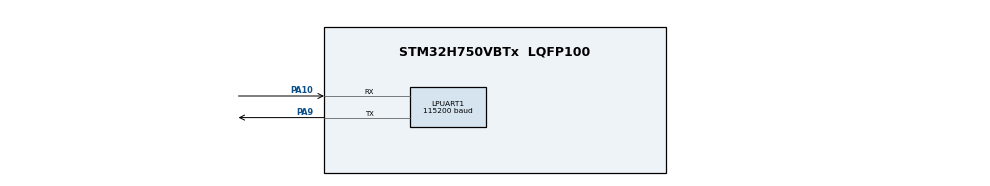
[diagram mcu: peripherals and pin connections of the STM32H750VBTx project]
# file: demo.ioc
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Bdma.LPUART1_RX.0.Direction=DMA_PERIPH_TO_MEMORY
Bdma.LPUART1_RX.0.EventEnable=DISABLE
Bdma.LPUART1_RX.0.Instance=BDMA_Channel0
Bdma.LPUART1_RX.0.MemDataAlignment=DMA_MDATAALIGN_BYTE
Bdma.LPUART1_RX.0.MemInc=DMA_MINC_ENABLE
Bdma.LPUART1_RX.0.Mode=DMA_NORMAL
Bdma.LPUART1_RX.0.PeriphDataAlignment=DMA_PDATAALIGN_BYTE
Bdma.LPUART1_RX.0.PeriphInc=DMA_PINC_DISABLE
Bdma.LPUART1_RX.0.Polarity=HAL_DMAMUX_REQ_GEN_RISING
Bdma.LPUART1_RX.0.Priority=DMA_PRIORITY_LOW
Bdma.LPUART1_RX.0.RequestNumber=1
Bdma.LPUART1_RX.0.SignalID=NONE
Bdma.LPUART1_RX.0.SyncEnable=DISABLE
Bdma.LPUART1_RX.0.SyncPolarity=HAL_DMAMUX_SYNC_NO_EVENT
Bdma.LPUART1_RX.0.SyncRequestNumber=1
Bdma.LPUART1_RX.0.SyncSignalID=NONE
Bdma.LPUART1_TX.1.Direction=DMA_MEMORY_TO_PERIPH
Bdma.LPUART1_TX.1.EventEnable=DISABLE
Bdma.LPUART1_TX.1.Instance=BDMA_Channel1
Bdma.LPUART1_TX.1.MemDataAlignment=DMA_MDATAALIGN_BYTE
Bdma.LPUART1_TX.1.MemInc=DMA_MINC_ENABLE
Bdma.LPUART1_TX.1.Mode=DMA_NORMAL
Bdma.LPUART1_TX.1.PeriphDataAlignment=DMA_PDATAALIGN_BYTE
Bdma.LPUART1_TX.1.PeriphInc=DMA_PINC_DISABLE
Bdma.LPUART1_TX.1.Polarity=HAL_DMAMUX_REQ_GEN_RISING
Bdma.LPUART1_TX.1.Priority=DMA_PRIORITY_LOW
Bdma.LPUART1_TX.1.RequestNumber=1
Bdma.LPUART1_TX.1.SignalID=NONE
Bdma.LPUART1_TX.1.SyncEnable=DISABLE
Bdma.LPUART1_TX.1.SyncPolarity=HAL_DMAMUX_SYNC_NO_EVENT
Bdma.LPUART1_TX.1.SyncRequestNumber=1
Bdma.LPUART1_TX.1.SyncSignalID=NONE
Bdma.Request0=LPUART1_RX
Bdma.Request1=LPUART1_TX
Bdma.RequestsNb=2
CORTEX_M7.AccessPermission-Cortex_Memory_Protection_Unit_Region2_Settings=MPU_REGION_FULL_ACCESS
CORTEX_M7.BaseAddress-Cortex_Memory_Protection_Unit_Region2_Settings=0x24000000
CORTEX_M7.Enable-Cortex_Memory_Protection_Unit_Region0_Settings=__NULL
CORTEX_M7.Enable-Cortex_Memory_Protection_Unit_Region2_Settings=MPU_REGION_ENABLE
CORTEX_M7.IsCacheable-Cortex_Memory_Protection_Unit_Region2_Settings=MPU_ACCESS_CACHEABLE
CORTEX_M7.IsShareable-Cortex_Memory_Protection_Unit_Region2_Settings=MPU_ACCESS_SHAREABLE
CORTEX_M7.MPU_Control=__NULL
CORTEX_M7.Size-Cortex_Memory_Protection_Unit_Region2_Settings=MPU_REGION_SIZE_512KB
LPUART1.BaudRate=115200
LPUART1.FIFOMode=UART_FIFOMODE_DISABLE
Mcu.Family=STM32H7
Mcu.Name=STM32H750VBTx
Mcu.Package=LQFP100
NVIC.BDMA_Channel0_IRQn=true\:0\:0\:false\:false\:true\:true\:true\:true
NVIC.BDMA_Channel1_IRQn=true\:0\:0\:false\:false\:true\:false\:true\:true
NVIC.LPUART1_IRQn=true\:0\:0\:false\:false\:true\:true\:true\:true
NVIC.PriorityGroup=NVIC_PRIORITYGROUP_4
PA10.Mode=Asynchronous
PA10.Signal=LPUART1_RX
PA9.Mode=Asynchronous
PA9.Signal=LPUART1_TX
PC14-OSC32_IN\ (OSC32_IN).Mode=LSE-External-Oscillator
PC14-OSC32_IN\ (OSC32_IN).Signal=RCC_OSC32_IN
PC15-OSC32_OUT\ (OSC32_OUT).Mode=LSE-External-Oscillator
PC15-OSC32_OUT\ (OSC32_OUT).Signal=RCC_OSC32_OUT
PH0-OSC_IN\ (PH0).Mode=HSE-External-Oscillator
PH0-OSC_IN\ (PH0).Signal=RCC_OSC_IN
PH1-OSC_OUT\ (PH1).Mode=HSE-External-Oscillator
PH1-OSC_OUT\ (PH1).Signal=RCC_OSC_OUT
ProjectManager.HeapSize=0x200
ProjectManager.StackSize=0x400
ProjectManager.TargetToolchain=MDK-ARM V5.32
RCC.ADCFreq_Value=129000000
RCC.APB1Freq_Value=64000000
RCC.APB2Freq_Value=32000000
RCC.APB3Freq_Value=32000000
RCC.APB4Freq_Value=64000000
RCC.CortexFreq_Value=64000000
RCC.D1PPRE=RCC_APB3_DIV2
RCC.D2PPRE2=RCC_APB2_DIV2
RCC.HCLKFreq_Value=64000000
RCC.SYSCLKFreq_VALUE=64000000
RCC.USBFreq_Value=129000000
board=custom

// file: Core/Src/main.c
/* USER CODE BEGIN Header */
/**
  ******************************************************************************
  * @file           : main.c
  * @brief          : Main program body
  ******************************************************************************
  * @attention
  *
  * Copyright (c) 2023 STMicroelectronics.
  * All rights reserved.
  *
  * This software is licensed under terms that can be found in the LICENSE file
  * in the root directory of this software component.
  * If no LICENSE file comes with this software, it is provided AS-IS.
  *
  ******************************************************************************
  */
/* USER CODE END Header */
#include "main.h"
#include "bdma.h"
#include "usart.h"
#include "gpio.h"

/* USER CODE BEGIN Includes */
#include "stdio.h"
#include "stm32h750xx.h"
/* USER CODE END Includes */

/* USER CODE BEGIN PV */
extern uint8_t rx_len;
extern uint8_t recv_end_flag;
extern uint8_t rx_buffer[200];
extern uint8_t tx_buffer[200];
extern DMA_HandleTypeDef hdma_lpuart1_tx;

/* USER CODE END PV */

void SystemClock_Config(void);

int main(void)
{

  /* MCU Configuration--------------------------------------------------------*/

  /* Reset of all peripherals, Initializes the Flash interface and the Systick. */
  HAL_Init();

  /* Configure the system clock */
  SystemClock_Config();

  /* Initialize all configured peripherals */
  MX_GPIO_Init();
  MX_BDMA_Init();
  MX_LPUART1_UART_Init();
  /* USER CODE BEGIN 2 */
	//开启串口空闲中断
	__HAL_UART_ENABLE_IT(&hlpuart1, UART_IT_IDLE);
	while(__HAL_UART_GET_FLAG(&hlpuart1,UART_FLAG_IDLE)==RESET);
	//开启DMA
	HAL_UART_Receive_DMA(&hlpuart1,rx_buffer,sizeof(rx_buffer));
	recv_end_flag=0;
	rx_len = 0;
//	printf("UART_IDLE_DMA接收不定长数据！\r\n");
	HAL_Delay(1000);
  /* USER CODE END 2 */

  /* Infinite loop */
  /* USER CODE BEGIN WHILE */
  while (1)
  {
		if(recv_end_flag ==1)
		{
			//printf("接收到的数据长度为%d\r\n",rx_len);

			MY_UART_Transmit(tx_buffer, rx_len);

			for(uint8_t i=0;i<rx_len;i++)
			{
				rx_buffer[i]=0;
			}
			rx_len=0;
			recv_end_flag=0;
		}
    /* USER CODE END WHILE */

  }
}

void SystemClock_Config(void)
{
  RCC_OscInitTypeDef RCC_OscInitStruct = {0};
  RCC_ClkInitTypeDef RCC_ClkInitStruct = {0};

  /** Supply configuration update enable
  */
  HAL_PWREx_ConfigSupply(PWR_LDO_SUPPLY);

  /** Configure the main internal regulator output voltage
  */
  __HAL_PWR_VOLTAGESCALING_CONFIG(PWR_REGULATOR_VOLTAGE_SCALE3);

  while(!__HAL_PWR_GET_FLAG(PWR_FLAG_VOSRDY)) {}

  /** Initializes the RCC Oscillators according to the specified parameters
  * in the RCC_OscInitTypeDef structure.
  */
  RCC_OscInitStruct.OscillatorType = RCC_OSCILLATORTYPE_HSI;
  RCC_OscInitStruct.HSIState = RCC_HSI_DIV1;
  RCC_OscInitStruct.HSICalibrationValue = RCC_HSICALIBRATION_DEFAULT;
  RCC_OscInitStruct.PLL.PLLState = RCC_PLL_NONE;
  if (HAL_RCC_OscConfig(&RCC_OscInitStruct) != HAL_OK)
  {
    Error_Handler();
  }

  /** Initializes the CPU, AHB and APB buses clocks
  */
  RCC_ClkInitStruct.ClockType = RCC_CLOCKTYPE_HCLK|RCC_CLOCKTYPE_SYSCLK
                              |RCC_CLOCKTYPE_PCLK1|RCC_CLOCKTYPE_PCLK2
                              |RCC_CLOCKTYPE_D3PCLK1|RCC_CLOCKTYPE_D1PCLK1;
  RCC_ClkInitStruct.SYSCLKSource = RCC_SYSCLKSOURCE_HSI;
  RCC_ClkInitStruct.SYSCLKDivider = RCC_SYSCLK_DIV1;
  RCC_ClkInitStruct.AHBCLKDivider = RCC_HCLK_DIV1;
  RCC_ClkInitStruct.APB3CLKDivider = RCC_APB3_DIV2;
  RCC_ClkInitStruct.APB1CLKDivider = RCC_APB1_DIV1;
  RCC_ClkInitStruct.APB2CLKDivider = RCC_APB2_DIV2;
  RCC_ClkInitStruct.APB4CLKDivider = RCC_APB4_DIV1;

  if (HAL_RCC_ClockConfig(&RCC_ClkInitStruct, FLASH_LATENCY_1) != HAL_OK)
  {
    Error_Handler();
  }
}

void Error_Handler(void)
{
  __disable_irq();
  while (1)
  {
  }
}
